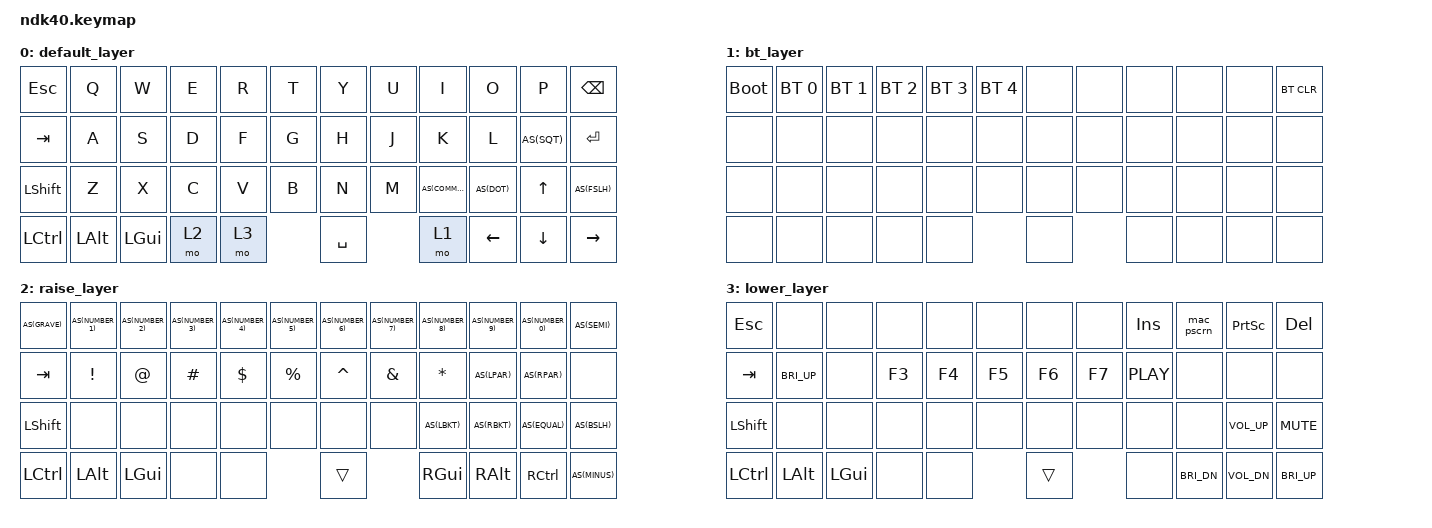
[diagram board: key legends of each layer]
#include <behaviors.dtsi>
#include <dt-bindings/zmk/bt.h>
#include <dt-bindings/zmk/keys.h>

#define AS(keycode) &as LS(keycode) keycode     // Autoshift Macro

/ {
    combos {
        compatible = "zmk,combos";

        combo_undo {
            bindings = <&kp LC(Z)>;
            key-positions = <25 26>;
            layers = <0>;
            timeout-ms = <50>;
        };

        combo_cut {
            bindings = <&kp LC(X)>;
            key-positions = <26 27>;
            layers = <0>;
            timeout-ms = <50>;
        };

        combo_copy {
            bindings = <&kp LC(C)>;
            key-positions = <27 28>;
            layers = <0>;
            timeout-ms = <50>;
        };

        combo_paste {
            bindings = <&kp LC(V)>;
            key-positions = <15 28>;
            layers = <0>;
            timeout-ms = <50>;
        };

        combo_backspace {
            bindings = <&kp BSPC>;
            key-positions = <9 10>;
            layers = <0>;
            timeout-ms = <50>;
        };

        combo_enter {
            bindings = <&kp RET>;
            key-positions = <21 22>;
            layers = <0>;
            timeout-ms = <50>;
        };
    }; // End combo

    behaviors {
        as: auto_shift {
            compatible = "zmk,behavior-hold-tap";
            #binding-cells = <2>;
            tapping_term_ms = <200>;
            quick_tap_ms = <0>;
            flavor = "tap-preferred";
            bindings = <&kp>, <&kp>;
        };
    }; // behaviors

    macros {
        mac_pscrn: mac_pscrn {
            compatible = "zmk,behavior-macro";
            #binding-cells = <0>;
            bindings = 
                <&macro_press &kp LSHFT &kp LCTRL>,
                <&macro_press &mo 2>,
                <&macro_tap AS(NUMBER_5)>,
                <&macro_release &mo 2>,
                <&macro_release &kp LSHFT &kp LCTRL>;
        };
    }; // macros

    keymap {
        compatible = "zmk,keymap";

        default_layer {
            //  --------------------------------------------------------
            //  |  ESC  |   Q   |   W   |   E   |   R   |   T   |   Y   |   U   |   I   |   O   |   P   |     BSPC     |
            //  |    Tab    |   A   |   S   |   D   |   F   |   G   |   H   |   J   |   K   |   L   |   :   |   Enter  |
            //  |     Shift    |   Z   |   X   |   C   |   V   |   B   |   N   |   M   |   ,   |   .   |  up   |   ?   |
            //  |    Ctrl   |    Alt    |    GUI    | lower | raise |     Space    |     fn    | left  | down  | right | 

            bindings = <
                &kp ESC    &kp Q    &kp W    &kp E  &kp R  &kp T      &kp Y  &kp U     &kp I     &kp O      &kp P      &kp BSPC  
                &kp TAB    &kp A    &kp S    &kp D  &kp F  &kp G      &kp H  &kp J     &kp K     &kp L      AS(SQT)    &kp RET
                &kp LSHFT  &kp Z    &kp X    &kp C  &kp V  &kp B      &kp N  &kp M     AS(COMMA) AS(DOT)    &kp UP    AS(FSLH)  
                &kp LCTRL  &kp LALT &kp LGUI &mo 2  &mo 3             &kp SPACE        &mo 1     &kp LEFT   &kp DOWN   &kp RIGHT
            >;
        };

        bt_layer {
            bindings = <
                &bootloader &bt BT_SEL 0  &bt BT_SEL 1  &bt BT_SEL 2  &bt BT_SEL 3  &bt BT_SEL 4  &none  &none  &none  &none  &none  &bt BT_CLR  
                &none       &none         &none         &none         &none         &none         &none  &none  &none  &none  &none  &none  
                &none       &none         &none         &none         &none         &none         &none  &none  &none  &none  &none  &none  
                &none       &none         &none         &none         &none                       &none         &none  &none  &none  &none
            >;
        };

        raise_layer {
            bindings = <
                AS(GRAVE)  AS(NUMBER_1)  AS(NUMBER_2)  AS(NUMBER_3)  AS(NUMBER_4)  AS(NUMBER_5)  AS(NUMBER_6)  AS(NUMBER_7)  AS(NUMBER_8)  AS(NUMBER_9)  AS(NUMBER_0)  AS(SEMI)
                &kp TAB    &kp EXCL      &kp AT        &kp HASH      &kp DLLR      &kp PRCNT     &kp CARET     &kp AMPS      &kp STAR      AS(LPAR)      AS(RPAR)      &none 
                &kp LSHFT  &none         &none         &none         &none         &none         &none         &none         AS(LBKT)      AS(RBKT)      AS(EQUAL)     AS(BSLH)  
                &kp LCTRL  &kp LALT      &kp LGUI      &none         &none                       &trans                      &kp RGUI      &kp RALT      &kp RCTRL     AS(MINUS)
            >;
        };

        lower_layer {
            bindings = <
                &kp ESC    &none         &none         &none         &none         &none         &none         &none         &kp INS       &mac_pscrn       &kp PSCRN     &kp DEL  
                &kp TAB    &kp C_BRI_UP  &none         &kp F3        &kp F4        &kp F5        &kp F6        &kp F7        &kp C_PLAY    &none            &none         &none  
                &kp LSHFT  &none         &none         &none         &none         &none         &none         &none         &none         &none            &kp C_VOL_UP  &kp C_MUTE  
                &kp LCTRL  &kp LALT      &kp LGUI      &none         &none                       &trans                      &none         &kp C_BRI_DN     &kp C_VOL_DN  &kp C_BRI_UP 
            >;
        };
    };
};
